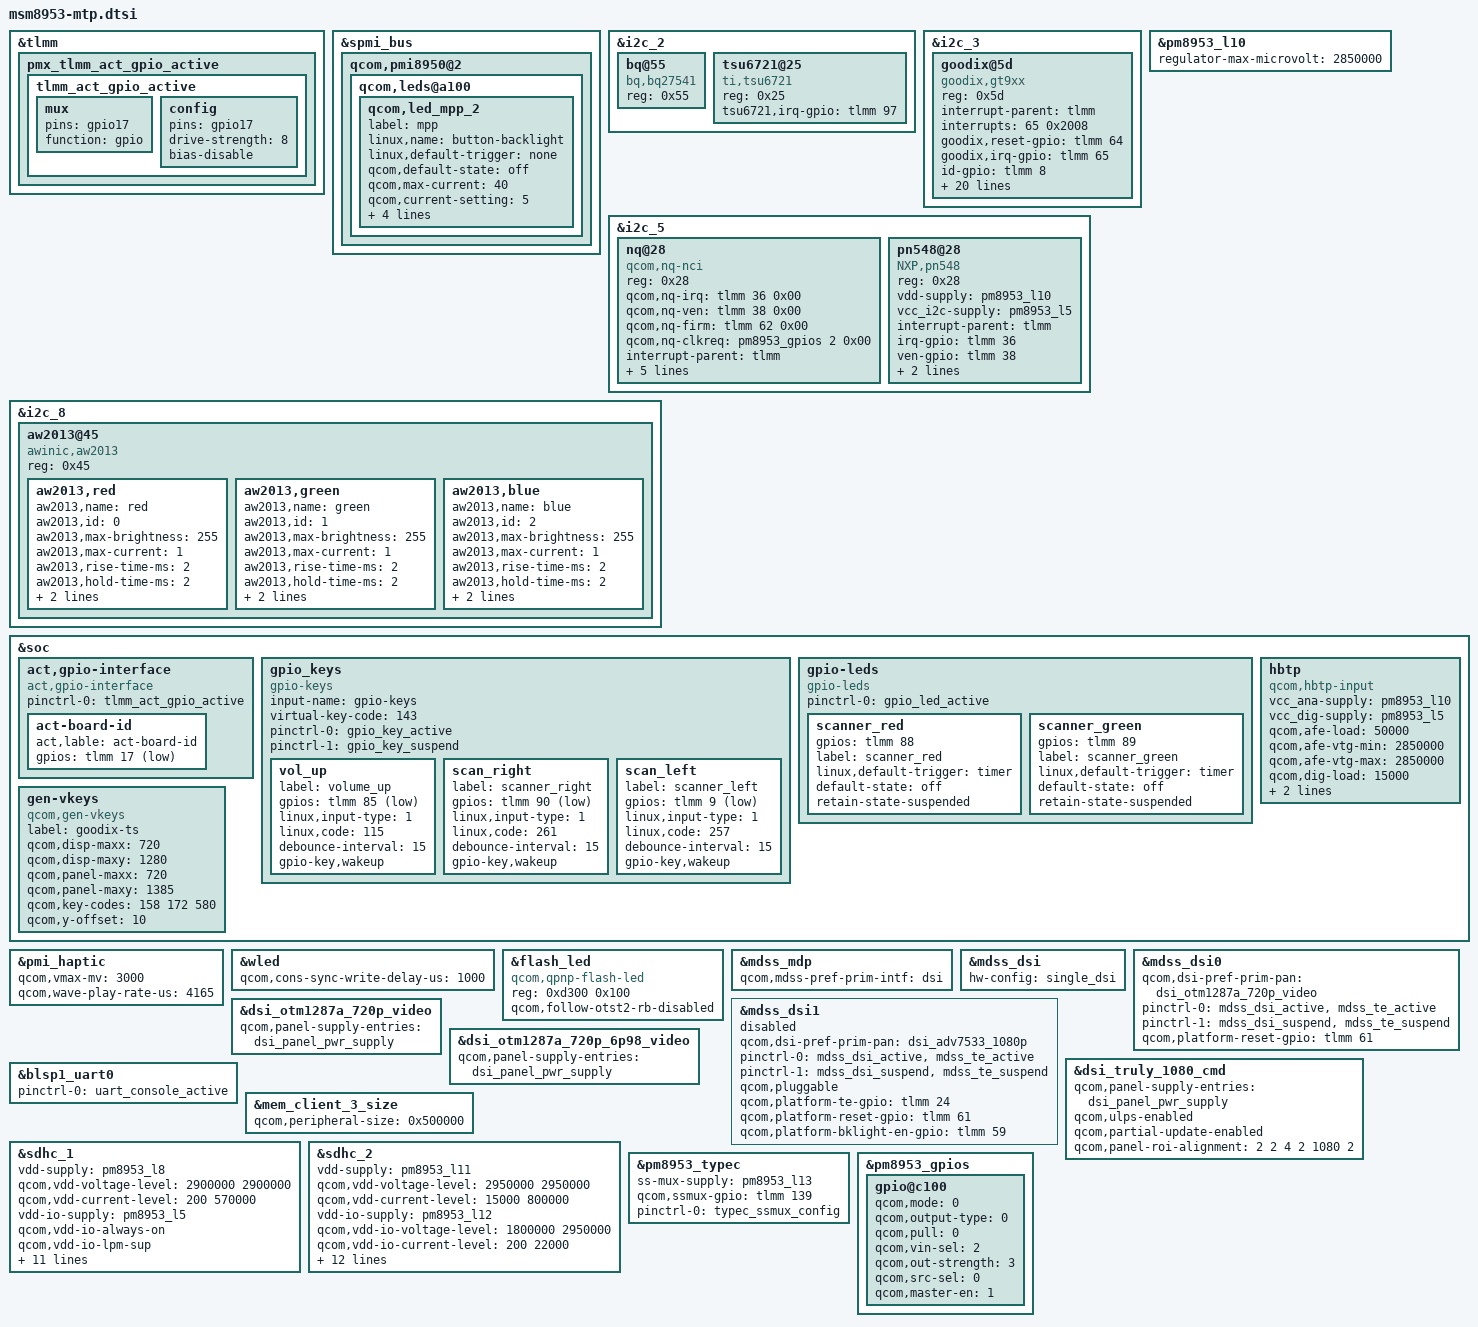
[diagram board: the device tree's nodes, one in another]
/*
 * Copyright (c) 2015-2017, The Linux Foundation. All rights reserved.
 *
 * This program is free software; you can redistribute it and/or modify
 * it under the terms of the GNU General Public License version 2 and
 * only version 2 as published by the Free Software Foundation.
 *
 * This program is distributed in the hope that it will be useful,
 * but WITHOUT ANY WARRANTY; without even the implied warranty of
 * MERCHANTABILITY or FITNESS FOR A PARTICULAR PURPOSE.  See the
 * GNU General Public License for more details.
 */

#include "msm8953-pinctrl.dtsi"
#include "msm8953-audio-mtp.dtsi"

&tlmm {
		pmx_tlmm_act_gpio_active {
			tlmm_act_gpio_active: tlmm_act_gpio_active {
				mux {
					pins = "gpio17";
					function = "gpio";
				};

				config {
					pins = "gpio17";
					drive-strength = <8>;
					bias-disable;
				};
			};
		};
};

/*
&spi_3 {  BLSP1 QUP3 
	spi-max-frequency = <16000000>;
	maxim_sti@0 {
		status = "disabled";
		compatible = "maxim,maxim_sti";
		reg = <0>;
		interrupt-parent = <&tlmm>;
		interrupts = <65 0>;
		spi-max-frequency = <16000000>;
		avdd-supply = <&pm8953_l10>;
		dvdd-supply = <&pm8953_l5>;
		maxim_sti,irq-gpio = <&tlmm 65 0x00>;
		maxim_sti,reset-gpio = <&tlmm 64 0x00>;
		maxim_sti,touch_fusion = "/vendor/bin/touch_fusion";
		maxim_sti,config_file = "/etc/firmware/qtc800s.cfg";
		maxim_sti,fw_name = "qtc800s.bin";
		pinctrl-names = "pmx_ts_active","pmx_ts_suspend",
						"pmx_ts_release";
		pinctrl-0 = <&ts_int_active &ts_reset_active>;
		pinctrl-1 = <&ts_int_suspend &ts_reset_suspend>;
		pinctrl-2 = <&ts_release>;
	};
};*/

&spmi_bus {
       qcom,pmi8950@2 {
               qcom,leds@a100 {
                       status = "okay";
                       qcom,led_mpp_2 {
                               label = "mpp";
                               linux,name = "button-backlight";
                               linux,default-trigger = "none";
                               qcom,default-state = "off";
                               qcom,max-current = <40>;
                               qcom,current-setting = <5>;
                               qcom,id = <6>;
                               qcom,mode = "manual";
                               qcom,source-sel = <1>;
                               qcom,mode-ctrl = <0x60>;
                       };
               };
       };
};

&i2c_2 {
       bq@55{
               compatible = "bq,bq27541";
               reg = <0x55>;
       };
       tsu6721@25 {
    	reg = <0x25>;
    	compatible = "ti,tsu6721";
    	tsu6721,irq-gpio = <&tlmm 97 0x02>; /* IRQF_TRIGGER_FALLING */
    };
};

&i2c_3 { /* BLSP1 QUP3 (TouchPanel) */
		status = "okay";
		goodix@5d {
			compatible = "goodix,gt9xx";
			reg = <0x5d>;
			interrupt-parent = <&tlmm>;
			interrupts = <65 0x2008>;
			goodix,reset-gpio = <&tlmm 64 0x00>;
			goodix,irq-gpio = <&tlmm 65 0x00>;
                        id-gpio = <&tlmm 8 0x00>;
			vdd-supply = <&pm8953_l10>;
			vcc-i2c-supply = <&pm8953_l6>;
			/* pins used by touchscreen */
			pinctrl-names = "pmx_ts_active","pmx_ts_suspend","pmx_ts_release";
			pinctrl-0 = <&ts_int_active &ts_reset_active>;
			//pinctrl-1 = <&ts_int_active &ts_reset_active>;
			pinctrl-1 = <&ts_int_suspend &ts_reset_suspend>;
			pinctrl-2 = <&ts_release>;
			goodix,panel-coords = <0 0 720 1440>;
			goodix,display-coords = <0 0 720 1280>;
			//goodix,display-coords = <0 0 1100 1756>;
			//goodix,panel-coords = <0 0 1100 1899>;
			goodix,button-map= <139 102 158>;
			goodix,product-id = "917D";
			goodix,enable-power-off;
			goodix,num_max_touches = <5>;
			goodix,soft_rst_dly = <20>;
			goodix,fw_name = "gtp_fw.bin";
			goodix,fw-vkey-support;
			goodix,i2c-pull-up;
			goodix,no-force-update;
			goodix,cfg-group0 = [
    47 D0 02 00 05 0A 0C 55 21 CF 
    2D 0F 55 46 05 F3 00 00 00 00 
    00 11 06 15 16 1A 14 86 26 AB 
    3C 3E D3 07 7C 06 00 C2 33 11 
    00 00 00 00 00 00 00 0A 0C 78 
    2A 28 5B 88 E0 A5 0A 1E 1E 04 
    A2 2B 00 8B 33 00 7A 3C 00 6B 
    47 00 5F 54 00 5F 18 30 50 00 
    F2 30 20 DD DD 27 00 20 00 00 
    00 00 00 00 53 64 00 04 0F 28 
    00 00 00 00 00 0A 50 00 00 00 
    00 28 10 0B 0C 11 12 0D 0E 13 
    14 0F 0A 09 08 07 06 05 04 03 
    02 01 00 FF FF FF FF FF FF FF 
    FF FF 00 02 04 05 06 08 1E 1F 
    20 22 24 2A FF FF FF FF FF 00 
    00 00 00 00 00 00 00 00 00 00 
    00 00 00 00 00 00 00 00 00 00 
    00 00 00 00 00 00 00 00 00 00 
    28 5A 00 00 00 00 00 00 00 00 
    00 00 00 00 00 00 00 00 00 00 
    00 00 00 00 00 00 00 00 00 00 
    00 00 00 00 00 00 03 01
			];

			// id-gpio high, finger,lcd_truly
			goodix,cfg-group1 = [
    42 D0 02 00 05 0A 75 1C 01 0F 
    1E 0F 46 32 03 05 00 00 00 00 
    00 00 05 18 1A 1E 14 90 30 AA 
    29 2B A6 0F 00 00 00 03 03 11 
    00 00 00 00 00 00 00 00 00 00 
    00 1A 4C 94 C5 02 07 00 00 04 
    8F 1F 00 78 27 00 66 31 00 59 
    3D 00 4F 4D 00 4F 00 00 00 00 
    00 00 00 00 00 00 00 00 00 00 
    00 00 00 00 00 00 00 00 00 00 
    00 00 00 00 00 08 01 01 00 00 
    00 00 00 01 04 05 06 07 08 09 
    0C 0D 0E 0F 10 11 14 15 16 17 
    18 19 00 00 00 00 00 00 00 00 
    00 00 19 1B 1C 1E 1F 20 21 22 
    23 24 25 26 27 28 29 2A 14 13 
    12 11 10 0F 0E 0D 0C 0A 08 07 
    06 04 02 00 00 00 00 00 00 00 
    00 00 00 00 82 01
			];
		};
};

&i2c_5 { /* BLSP2 QUP1 (NFC) */
	nq@28 {
		compatible = "qcom,nq-nci";
		reg = <0x28>;
		qcom,nq-irq = <&tlmm 36 0x00>;
		qcom,nq-ven = <&tlmm 38 0x00>;
		qcom,nq-firm = <&tlmm 62 0x00>;
		qcom,nq-clkreq = <&pm8953_gpios 2 0x00>;
		interrupt-parent = <&tlmm>;
		qcom,clk-src = "BBCLK2";
		/*interrupts = <36 0>;*/
		interrupt-names = "nfc_irq";
		pinctrl-names = "nfc_active", "nfc_suspend";
		pinctrl-0 = <&nfc_int_active >;
		pinctrl-1 = <&nfc_int_suspend>;
		clocks = <&clock_gcc clk_bb_clk2_pin>;
		clock-names = "ref_clk";
		chip-type = <0x41>;
	};
        pn548@28 {
                compatible = "NXP,pn548";
                reg = <0x28>;
                vdd-supply = <&pm8953_l10>;
                vcc_i2c-supply = <&pm8953_l5>;
                interrupt-parent = <&tlmm>;
                /*interrupts = <36 0x0>;*/
                irq-gpio = <&tlmm 36 0x00>;
                ven-gpio = <&tlmm 38 0x00>;
                firm-gpio = <&tlmm 62 0x00>;
		chip-type = <0x28>;
       };
};


&i2c_8 {
	aw2013@45 { 
		compatible = "awinic,aw2013";
		reg = <0x45>;
		//vdd-supply = <&pm8937_l17>;
		//vcc-supply = <&pm8937_l6>;
		//qcom,chgledpwr-gpio = <&tlmm 68 0x00>;
        //aw2013,gpio-vcc-en = <&tlmm 68 0x00>;
		aw2013,red { 
			aw2013,name = "red";
			aw2013,id = <0>;
			aw2013,max-brightness = <255>;
			aw2013,max-current = <1>;
			aw2013,rise-time-ms = <2>;
			aw2013,hold-time-ms = <2>;
			aw2013,fall-time-ms = <2>;
			aw2013,off-time-ms = <2>; };
		aw2013,green { 
			aw2013,name = "green";
			aw2013,id = <1>;
			aw2013,max-brightness = <255>;
			aw2013,max-current = <1>;
			aw2013,rise-time-ms = <2>;
			aw2013,hold-time-ms = <2>;
			aw2013,fall-time-ms = <2>;
			aw2013,off-time-ms = <2>; };
		aw2013,blue { 
			aw2013,name = "blue";
			aw2013,id = <2>;
			aw2013,max-brightness = <255>;
			aw2013,max-current = <1>;
			aw2013,rise-time-ms = <2>;
			aw2013,hold-time-ms = <2>;
			aw2013,fall-time-ms = <2>;
			aw2013,off-time-ms = <2>; }; 
		}; 

};
&pm8953_l10 {
	regulator-max-microvolt = <2850000>;
};

&soc {
        act,gpio-interface {
                compatible = "act,gpio-interface";

		pinctrl-names = "act_gpio_active";
		pinctrl-0 = <&tlmm_act_gpio_active>;

                act-board-id {
                        act,lable = "act-board-id";
                        gpios = <&tlmm 17 33>;
                };
        };

	gpio_keys {
		compatible = "gpio-keys";
		input-name = "gpio-keys";
		virtual-key-code = <143>;
		pinctrl-names = "tlmm_gpio_key_active","tlmm_gpio_key_suspend";
		pinctrl-0 = <&gpio_key_active>;
		pinctrl-1 = <&gpio_key_suspend>;

		vol_up {
			label = "volume_up";
			gpios = <&tlmm 85 0x1>;
			linux,input-type = <1>;
			linux,code = <115>;
			debounce-interval = <15>;
			gpio-key,wakeup;
		};

		scan_right {
			label = "scanner_right";
			gpios = <&tlmm 90 0x1>;
			linux,input-type = <1>;
			linux,code = <261>;
			debounce-interval = <15>;
			gpio-key,wakeup;
		};

		scan_left {
			label = "scanner_left";
			gpios = <&tlmm 9 0x1>;
			linux,input-type = <1>;
			linux,code = <257>;
			debounce-interval = <15>;
			gpio-key,wakeup;
		};
	};

    gpio-leds {
           compatible = "gpio-leds";
           status = "okay";
           pinctrl-names = "default";
           pinctrl-0 = <&gpio_led_active>;
           /*pinctrl-1 = <&gpio_led_suspend>; */
           /*
            * SCANNER_REDLED_EN       GPIO_88
            * SCANNER_GREENLED_EN     GPIO_89
            */
           scanner_red {
               gpios = <&tlmm 88 0>;
               label = "scanner_red";
               linux,default-trigger = "timer";
               default-state = "off";
               retain-state-suspended;
           };
           scanner_green {
               gpios = <&tlmm 89 0>;
               label = "scanner_green";
               linux,default-trigger = "timer";
               default-state = "off";
               retain-state-suspended;
           };

       };
	hbtp {
		compatible = "qcom,hbtp-input";
		vcc_ana-supply = <&pm8953_l10>;
		vcc_dig-supply = <&pm8953_l5>;
		qcom,afe-load = <50000>;
		qcom,afe-vtg-min = <2850000>;
		qcom,afe-vtg-max = <2850000>;
		qcom,dig-load = <15000>;
		qcom,dig-vtg-min = <1800000>;
		qcom,dig-vtg-max = <1800000>;
	};
};

&pmi_haptic{
    //Modified by Chenqi for KUN-268 on 2018/3/20 begin
	//qcom,actuator-type = "lra";
	//qcom,lra-auto-res-mode="qwd";
	//qcom,lra-high-z="opt1";
	//qcom,lra-res-cal-period = <0>;
	qcom,vmax-mv = <3000>;
	//Modified by Chenqi for KUN-268 on 2018/3/20 end
	qcom,wave-play-rate-us = <4165>;
};

&wled {
	qcom,cons-sync-write-delay-us = <1000>;
};

&flash_led {
	compatible = "qcom,qpnp-flash-led";
	reg = <0xd300 0x100>;
	qcom,follow-otst2-rb-disabled;
};

#include "msm8953-mdss-panels.dtsi"

&mdss_mdp {
	qcom,mdss-pref-prim-intf = "dsi";
};

&mdss_dsi {
	hw-config = "single_dsi";
};

&mdss_dsi0 {
	qcom,dsi-pref-prim-pan = <&dsi_otm1287a_720p_video>;
	pinctrl-names = "mdss_default", "mdss_sleep";
	pinctrl-0 = <&mdss_dsi_active &mdss_te_active>;
	pinctrl-1 = <&mdss_dsi_suspend &mdss_te_suspend>;

	//qcom,platform-te-gpio = <&tlmm 24 0>;
	qcom,platform-reset-gpio = <&tlmm 61 0>;
	//qcom,platform-bklight-en-gpio = <&tlmm 59 0>;
};

&mdss_dsi1 {
	status = "disabled";
	qcom,dsi-pref-prim-pan = <&dsi_adv7533_1080p>;
	pinctrl-names = "mdss_default", "mdss_sleep";
	pinctrl-0 = <&mdss_dsi_active &mdss_te_active>;
	pinctrl-1 = <&mdss_dsi_suspend &mdss_te_suspend>;

	qcom,pluggable;
	qcom,platform-te-gpio = <&tlmm 24 0>;
	qcom,platform-reset-gpio = <&tlmm 61 0>;
	qcom,platform-bklight-en-gpio = <&tlmm 59 0>;
};

&dsi_otm1287a_720p_video {
	qcom,panel-supply-entries = <&dsi_panel_pwr_supply>;
	//qcom,mdss-dsi-pan-enable-dynamic-fps;
	//qcom,mdss-dsi-pan-fps-update = "dfps_immediate_clk_mode";
};
/****add this code for PWV_PROJECT_IDH63 lcd compatibility****/
&dsi_otm1287a_720p_6p98_video {
        qcom,panel-supply-entries = <&dsi_panel_pwr_supply>;
};
/****add this code for PWV_PROJECT_IDH63 lcd compatibility****/
&dsi_truly_1080_cmd {
	qcom,panel-supply-entries = <&dsi_panel_pwr_supply>;
	qcom,ulps-enabled;
	qcom,partial-update-enabled;
	qcom,panel-roi-alignment = <2 2 4 2 1080 2>;
};

&blsp1_uart0 {
	status = "ok";
	pinctrl-names = "default";
	pinctrl-0 = <&uart_console_active>;
};

&mem_client_3_size {
	qcom,peripheral-size = <0x500000>;
};

&sdhc_1 {
	/* device core power supply */
	vdd-supply = <&pm8953_l8>;
	qcom,vdd-voltage-level = <2900000 2900000>;
	qcom,vdd-current-level = <200 570000>;

	/* device communication power supply */
	vdd-io-supply = <&pm8953_l5>;
	qcom,vdd-io-always-on;
	qcom,vdd-io-lpm-sup;
	qcom,vdd-io-voltage-level = <1800000 1800000>;
	qcom,vdd-io-current-level = <200 325000>;

	pinctrl-names = "active", "sleep";
	pinctrl-0 = <&sdc1_clk_on &sdc1_cmd_on &sdc1_data_on  &sdc1_rclk_on>;
	pinctrl-1 = <&sdc1_clk_off &sdc1_cmd_off &sdc1_data_off &sdc1_rclk_off>;

	qcom,clk-rates = <400000 20000000 25000000 50000000 100000000 192000000
								384000000>;
	qcom,nonremovable;
	qcom,bus-speed-mode = "HS400_1p8v", "HS200_1p8v", "DDR_1p8v";

	status = "ok";
};

&sdhc_2 {
	/* device core power supply */
	vdd-supply = <&pm8953_l11>;
	qcom,vdd-voltage-level = <2950000 2950000>;
	qcom,vdd-current-level = <15000 800000>;

	/* device communication power supply */
	vdd-io-supply = <&pm8953_l12>;
	qcom,vdd-io-voltage-level = <1800000 2950000>;
	qcom,vdd-io-current-level = <200 22000>;

	pinctrl-names = "active", "sleep";
	pinctrl-0 = <&sdc2_clk_on &sdc2_cmd_on &sdc2_data_on>;
	pinctrl-1 = <&sdc2_clk_off &sdc2_cmd_off &sdc2_data_off>;

	#address-cells = <0>;
	interrupt-parent = <&sdhc_2>;
	interrupts = <0 1 2>;
	#interrupt-cells = <1>;
	interrupt-map-mask = <0xffffffff>;
	interrupt-map = <0 &intc 0 125 0
		1 &intc 0 221 0>;
	interrupt-names = "hc_irq", "pwr_irq";

	qcom,clk-rates = <400000 20000000 25000000 50000000 100000000
								200000000>;
	qcom,bus-speed-mode = "SDR12", "SDR25", "SDR50", "DDR50", "SDR104";

	status = "ok";
};

&pm8953_typec {
	ss-mux-supply = <&pm8953_l13>;
	qcom,ssmux-gpio = <&tlmm 139 GPIO_ACTIVE_HIGH>;
	pinctrl-names = "default";
	pinctrl-0 = <&typec_ssmux_config>;
};

&pm8953_gpios {
	/* GPIO 2 (NFC_CLK_REQ) */
	gpio@c100 {
		qcom,mode = <0>;
		qcom,output-type = <0>;
		qcom,pull = <0>;
		qcom,vin-sel = <2>;
		qcom,out-strength = <3>;
		qcom,src-sel = <0>;
		qcom,master-en = <1>;
		status = "okay";
	};
};
&soc {
    gen-vkeys {
    	compatible = "qcom,gen-vkeys";
    	label = "goodix-ts";
    	qcom,disp-maxx = <720>;
    	qcom,disp-maxy = <1280>;
    	qcom,panel-maxx = <720>;
    	qcom,panel-maxy = <1385>;
    	qcom,key-codes = <158 172 580>;
    	qcom,y-offset = <10>;
    };
};
